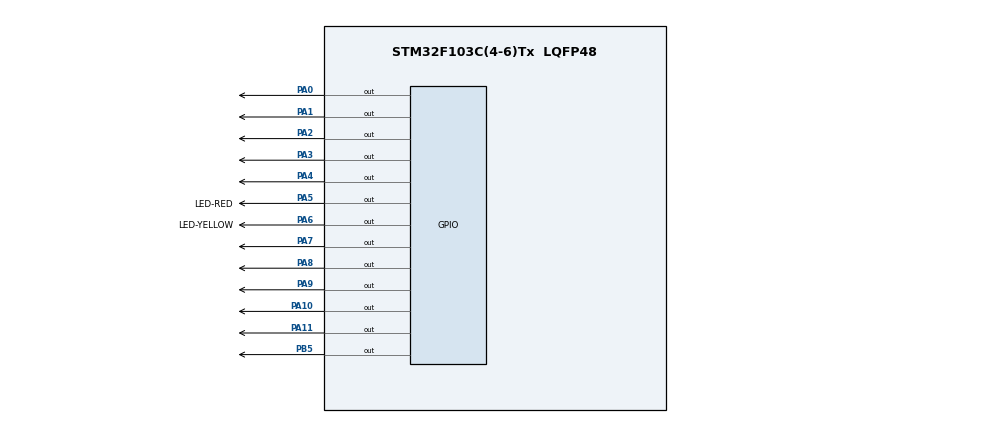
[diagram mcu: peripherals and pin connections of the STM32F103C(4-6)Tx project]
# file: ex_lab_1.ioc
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Mcu.Family=STM32F1
Mcu.Name=STM32F103C(4-6)Tx
Mcu.Package=LQFP48
NVIC.PriorityGroup=NVIC_PRIORITYGROUP_4
PA0-WKUP.Signal=GPIO_Output
PA1.Signal=GPIO_Output
PA10.Signal=GPIO_Output
PA11.Signal=GPIO_Output
PA2.Signal=GPIO_Output
PA3.Signal=GPIO_Output
PA4.Signal=GPIO_Output
PA5.GPIO_Label=LED-RED
PA5.Signal=GPIO_Output
PA6.GPIO_Label=LED-YELLOW
PA6.Signal=GPIO_Output
PA7.Signal=GPIO_Output
PA8.Signal=GPIO_Output
PA9.Signal=GPIO_Output
PB5.Signal=GPIO_Output
ProjectManager.HeapSize=0x200
ProjectManager.StackSize=0x400
ProjectManager.TargetToolchain=STM32CubeIDE
RCC.APB1Freq_Value=8000000
RCC.APB2Freq_Value=8000000
board=custom

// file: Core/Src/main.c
/* USER CODE BEGIN Header */
/**
  ******************************************************************************
  * @file           : main.c
  * @brief          : Main program body
  ******************************************************************************
  * @attention
  *
  * Copyright (c) 2023 STMicroelectronics.
  * All rights reserved.
  *
  * This software is licensed under terms that can be found in the LICENSE file
  * in the root directory of this software component.
  * If no LICENSE file comes with this software, it is provided AS-IS.
  *
  ******************************************************************************
  */
/* USER CODE END Header */
#include "main.h"

/* USER CODE BEGIN PD */
#define RED1_GREEN2 0
#define RED1_YELLOW2 1
#define GREEN1_RED2 2
#define YELLOW1_RED2 3
/* USER CODE END PD */

void SystemClock_Config(void);
void display7SEG(int num){
	switch(num){
	case 0:
			HAL_GPIO_WritePin(GPIOA, GPIO_PIN_0, 1);
			HAL_GPIO_WritePin(GPIOA, GPIO_PIN_1, 0);
			HAL_GPIO_WritePin(GPIOA, GPIO_PIN_2, 0);
			HAL_GPIO_WritePin(GPIOA, GPIO_PIN_3, 0);
			HAL_GPIO_WritePin(GPIOA, GPIO_PIN_4, 0);
			HAL_GPIO_WritePin(GPIOA, GPIO_PIN_5, 0);
			HAL_GPIO_WritePin(GPIOA, GPIO_PIN_6, 0);
			break;
		case 1:
			HAL_GPIO_WritePin(GPIOA, GPIO_PIN_0, 1);
			HAL_GPIO_WritePin(GPIOA, GPIO_PIN_1, 0);
			HAL_GPIO_WritePin(GPIOA, GPIO_PIN_2, 0);
			HAL_GPIO_WritePin(GPIOA, GPIO_PIN_3, 1);
			HAL_GPIO_WritePin(GPIOA, GPIO_PIN_4, 1);
			HAL_GPIO_WritePin(GPIOA, GPIO_PIN_5, 1);
			HAL_GPIO_WritePin(GPIOA, GPIO_PIN_6, 1);
			break;
		case 2:
			HAL_GPIO_WritePin(GPIOA, GPIO_PIN_0, 0);
			HAL_GPIO_WritePin(GPIOA, GPIO_PIN_1, 1);
			HAL_GPIO_WritePin(GPIOA, GPIO_PIN_2, 0);
			HAL_GPIO_WritePin(GPIOA, GPIO_PIN_3, 0);
			HAL_GPIO_WritePin(GPIOA, GPIO_PIN_4, 1);
			HAL_GPIO_WritePin(GPIOA, GPIO_PIN_5, 0);
			HAL_GPIO_WritePin(GPIOA, GPIO_PIN_6, 0);
			break;
		case 3:
			HAL_GPIO_WritePin(GPIOA, GPIO_PIN_0, 0);
			HAL_GPIO_WritePin(GPIOA, GPIO_PIN_1, 0);
			HAL_GPIO_WritePin(GPIOA, GPIO_PIN_2, 0);
			HAL_GPIO_WritePin(GPIOA, GPIO_PIN_3, 0);
			HAL_GPIO_WritePin(GPIOA, GPIO_PIN_4, 1);
			HAL_GPIO_WritePin(GPIOA, GPIO_PIN_5, 1);
			HAL_GPIO_WritePin(GPIOA, GPIO_PIN_6, 0);
			break;
		case 4:
			HAL_GPIO_WritePin(GPIOA, GPIO_PIN_0, 0);
			HAL_GPIO_WritePin(GPIOA, GPIO_PIN_1, 0);
			HAL_GPIO_WritePin(GPIOA, GPIO_PIN_2, 0);
			HAL_GPIO_WritePin(GPIOA, GPIO_PIN_3, 1);
			HAL_GPIO_WritePin(GPIOA, GPIO_PIN_4, 0);
			HAL_GPIO_WritePin(GPIOA, GPIO_PIN_5, 1);
			HAL_GPIO_WritePin(GPIOA, GPIO_PIN_6, 1);
			break;
		case 5:
			HAL_GPIO_WritePin(GPIOA, GPIO_PIN_0, 0);
			HAL_GPIO_WritePin(GPIOA, GPIO_PIN_1, 0);
			HAL_GPIO_WritePin(GPIOA, GPIO_PIN_2, 1);
			HAL_GPIO_WritePin(GPIOA, GPIO_PIN_3, 0);
			HAL_GPIO_WritePin(GPIOA, GPIO_PIN_4, 0);
			HAL_GPIO_WritePin(GPIOA, GPIO_PIN_5, 1);
			HAL_GPIO_WritePin(GPIOA, GPIO_PIN_6, 0);
			break;
		case 6:
			HAL_GPIO_WritePin(GPIOA, GPIO_PIN_0, 0);
			HAL_GPIO_WritePin(GPIOA, GPIO_PIN_1, 0);
			HAL_GPIO_WritePin(GPIOA, GPIO_PIN_2, 1);
			HAL_GPIO_WritePin(GPIOA, GPIO_PIN_3, 0);
			HAL_GPIO_WritePin(GPIOA, GPIO_PIN_4, 0);
			HAL_GPIO_WritePin(GPIOA, GPIO_PIN_5, 0);
			HAL_GPIO_WritePin(GPIOA, GPIO_PIN_6, 0);
			break;
		case 7:
			HAL_GPIO_WritePin(GPIOA, GPIO_PIN_0, 1);
			HAL_GPIO_WritePin(GPIOA, GPIO_PIN_1, 0);
			HAL_GPIO_WritePin(GPIOA, GPIO_PIN_2, 0);
			HAL_GPIO_WritePin(GPIOA, GPIO_PIN_3, 0);
			HAL_GPIO_WritePin(GPIOA, GPIO_PIN_4, 1);
			HAL_GPIO_WritePin(GPIOA, GPIO_PIN_5, 1);
			HAL_GPIO_WritePin(GPIOA, GPIO_PIN_6, 1);
			break;
		case 8:
			HAL_GPIO_WritePin(GPIOA, GPIO_PIN_0, 0);
			HAL_GPIO_WritePin(GPIOA, GPIO_PIN_1, 0);
			HAL_GPIO_WritePin(GPIOA, GPIO_PIN_2, 0);
			HAL_GPIO_WritePin(GPIOA, GPIO_PIN_3, 0);
			HAL_GPIO_WritePin(GPIOA, GPIO_PIN_4, 0);
			HAL_GPIO_WritePin(GPIOA, GPIO_PIN_5, 0);
			HAL_GPIO_WritePin(GPIOA, GPIO_PIN_6, 0);
			break;
		case 9:
			HAL_GPIO_WritePin(GPIOA, GPIO_PIN_0, 0);
			HAL_GPIO_WritePin(GPIOA, GPIO_PIN_1, 0);
			HAL_GPIO_WritePin(GPIOA, GPIO_PIN_2, 0);
			HAL_GPIO_WritePin(GPIOA, GPIO_PIN_3, 0);
			HAL_GPIO_WritePin(GPIOA, GPIO_PIN_4, 0);
			HAL_GPIO_WritePin(GPIOA, GPIO_PIN_5, 1);
			HAL_GPIO_WritePin(GPIOA, GPIO_PIN_6, 0);
			break;
		default:
			HAL_GPIO_WritePin(GPIOA, GPIO_PIN_0, 1);
			HAL_GPIO_WritePin(GPIOA, GPIO_PIN_1, 1);
			HAL_GPIO_WritePin(GPIOA, GPIO_PIN_2, 1);
			HAL_GPIO_WritePin(GPIOA, GPIO_PIN_3, 1);
			HAL_GPIO_WritePin(GPIOA, GPIO_PIN_4, 1);
			HAL_GPIO_WritePin(GPIOA, GPIO_PIN_5, 1);
			HAL_GPIO_WritePin(GPIOA, GPIO_PIN_6, 1);
		}
	}

static void MX_GPIO_Init(void);

int main(void)
{

  /* MCU Configuration--------------------------------------------------------*/

  /* Reset of all peripherals, Initializes the Flash interface and the Systick. */
  HAL_Init();

  /* Configure the system clock */
  SystemClock_Config();

  /* Initialize all configured peripherals */
  MX_GPIO_Init();

  /* Infinite loop */
  /* USER CODE BEGIN WHILE */
  	int currentState=0;
  	int counter=3;
  	int nextState=1;
  	HAL_GPIO_WritePin(GPIOA, GPIO_PIN_0, 0);
	HAL_GPIO_WritePin(GPIOA, GPIO_PIN_1, 0);
	HAL_GPIO_WritePin(GPIOA, GPIO_PIN_2, 0);
	HAL_GPIO_WritePin(GPIOA, GPIO_PIN_3, 0);
	HAL_GPIO_WritePin(GPIOA, GPIO_PIN_4, 0);
	HAL_GPIO_WritePin(GPIOA, GPIO_PIN_5, 0);
	HAL_GPIO_WritePin(GPIOA, GPIO_PIN_6, 0);
  	HAL_GPIO_WritePin(GPIOA, GPIO_PIN_7, 0);
  	HAL_GPIO_WritePin(GPIOA, GPIO_PIN_8, 0);
  	HAL_GPIO_WritePin(GPIOA, GPIO_PIN_9, 0);
  	HAL_GPIO_WritePin(GPIOA, GPIO_PIN_10, 0);
  	HAL_GPIO_WritePin(GPIOA, GPIO_PIN_11, 0);
  	HAL_GPIO_WritePin(GPIOA, GPIO_PIN_12, 0);
  while (1)
    {
	  display7SEG(counter);
	  switch (currentState) {
			case RED1_GREEN2:
				HAL_GPIO_WritePin(GPIOA, GPIO_PIN_7, 0);
				HAL_GPIO_WritePin(GPIOA, GPIO_PIN_8, 1);
				HAL_GPIO_WritePin(GPIOA, GPIO_PIN_9, 1);
				HAL_GPIO_WritePin(GPIOA, GPIO_PIN_10, 1);
				HAL_GPIO_WritePin(GPIOA, GPIO_PIN_11, 1);
				HAL_GPIO_WritePin(GPIOA, GPIO_PIN_12, 0);
				if (!counter) {
					nextState=RED1_YELLOW2;
					counter=2;
				}
				break;
			case RED1_YELLOW2:
				HAL_GPIO_WritePin(GPIOA, GPIO_PIN_8, 0);
				HAL_GPIO_WritePin(GPIOA, GPIO_PIN_12, 1);
				if (!counter) {
					nextState=GREEN1_RED2;
					counter=3;
				}
				break;
			case GREEN1_RED2:
				HAL_GPIO_WritePin(GPIOA, GPIO_PIN_7, 1);
				HAL_GPIO_WritePin(GPIOA, GPIO_PIN_9, 0);
				HAL_GPIO_WritePin(GPIOA, GPIO_PIN_10, 0);
				HAL_GPIO_WritePin(GPIOA, GPIO_PIN_11, 1);
				if (!counter) {
					nextState=YELLOW1_RED2;
					counter=2;
				}
				break;
			case YELLOW1_RED2:
				HAL_GPIO_WritePin(GPIOA, GPIO_PIN_8, 0);
				HAL_GPIO_WritePin(GPIOA, GPIO_PIN_9, 1);
				if (!counter) {
					nextState=RED1_GREEN2;
					counter=3;
				}
				break;
			}

	  	  currentState = nextState;
	  	  counter--;
//	  	  if(counter<0){
//	  		  counter=3;
//	  	  }

		  HAL_Delay(1000);
    }

 }

void SystemClock_Config(void)
{
  RCC_OscInitTypeDef RCC_OscInitStruct = {0};
  RCC_ClkInitTypeDef RCC_ClkInitStruct = {0};

  /** Initializes the RCC Oscillators according to the specified parameters
  * in the RCC_OscInitTypeDef structure.
  */
  RCC_OscInitStruct.OscillatorType = RCC_OSCILLATORTYPE_HSI;
  RCC_OscInitStruct.HSIState = RCC_HSI_ON;
  RCC_OscInitStruct.HSICalibrationValue = RCC_HSICALIBRATION_DEFAULT;
  RCC_OscInitStruct.PLL.PLLState = RCC_PLL_NONE;
  if (HAL_RCC_OscConfig(&RCC_OscInitStruct) != HAL_OK)
  {
    Error_Handler();
  }

  /** Initializes the CPU, AHB and APB buses clocks
  */
  RCC_ClkInitStruct.ClockType = RCC_CLOCKTYPE_HCLK|RCC_CLOCKTYPE_SYSCLK
                              |RCC_CLOCKTYPE_PCLK1|RCC_CLOCKTYPE_PCLK2;
  RCC_ClkInitStruct.SYSCLKSource = RCC_SYSCLKSOURCE_HSI;
  RCC_ClkInitStruct.AHBCLKDivider = RCC_SYSCLK_DIV1;
  RCC_ClkInitStruct.APB1CLKDivider = RCC_HCLK_DIV1;
  RCC_ClkInitStruct.APB2CLKDivider = RCC_HCLK_DIV1;

  if (HAL_RCC_ClockConfig(&RCC_ClkInitStruct, FLASH_LATENCY_0) != HAL_OK)
  {
    Error_Handler();
  }
}

static void MX_GPIO_Init(void)
{
  GPIO_InitTypeDef GPIO_InitStruct = {0};

  /* GPIO Ports Clock Enable */
  __HAL_RCC_GPIOA_CLK_ENABLE();

  /*Configure GPIO pin Output Level */
  HAL_GPIO_WritePin(GPIOA, LED_RED_Pin|LED_YELLOW_Pin, GPIO_PIN_RESET);

  /*Configure GPIO pins : LED_RED_Pin LED_YELLOW_Pin */
  GPIO_InitStruct.Pin = LED_RED_Pin|LED_YELLOW_Pin;
  GPIO_InitStruct.Mode = GPIO_MODE_OUTPUT_PP;
  GPIO_InitStruct.Pull = GPIO_NOPULL;
  GPIO_InitStruct.Speed = GPIO_SPEED_FREQ_LOW;
  HAL_GPIO_Init(GPIOA, &GPIO_InitStruct);

}

void Error_Handler(void)
{
  __disable_irq();
  while (1)
  {
  }
}
